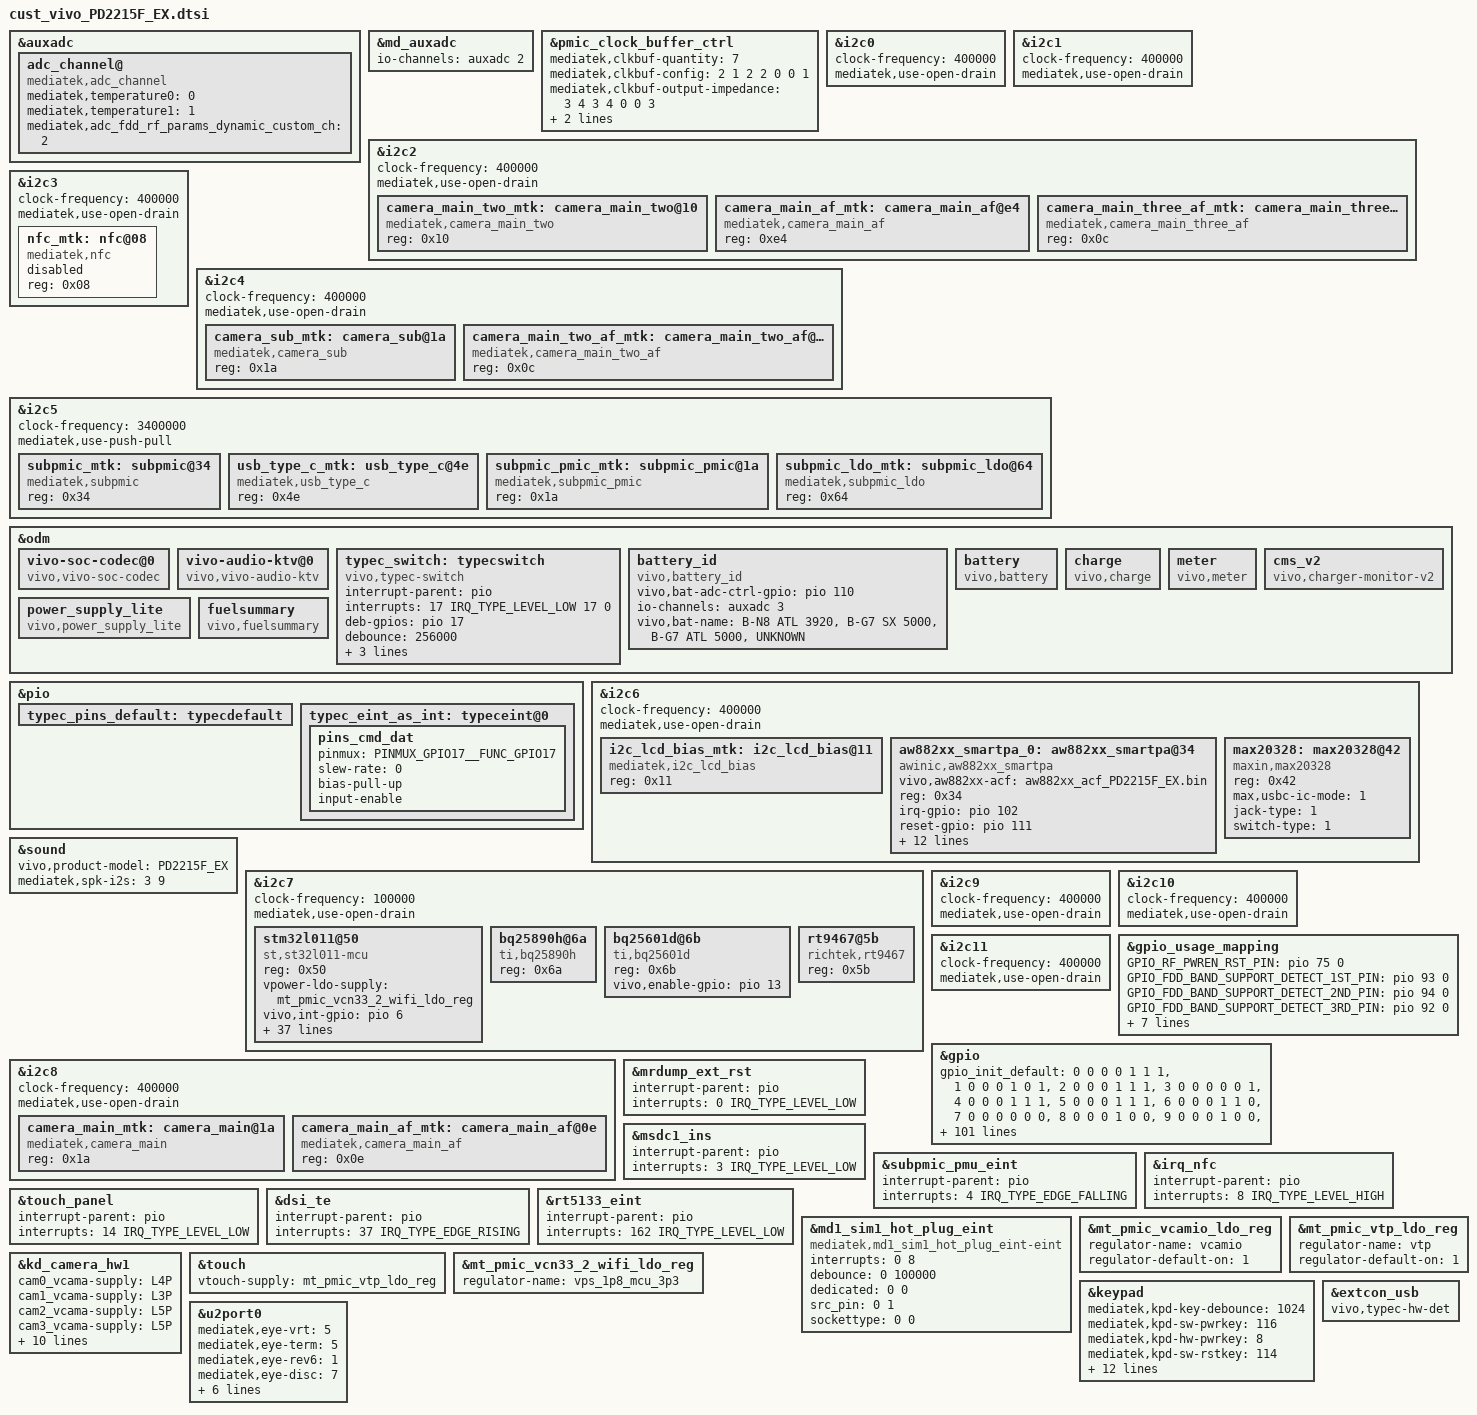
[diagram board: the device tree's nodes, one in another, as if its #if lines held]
/*
* Generated by MTK SP DrvGen Version: 3.5.160809 for MT6877.
* 2022-03-25 15:20:36
* Do Not Modify The File.
* Copyright Mediatek Inc. (c) 2016.
*/

/*************************
* ADC DTSI File
*************************/
#include <dt-bindings/pinctrl/mt6877-pinfunc.h>

&auxadc {
adc_channel@ {
	compatible = "mediatek,adc_channel";
	mediatek,temperature0 = <0>;
	mediatek,temperature1 = <1>;
	mediatek,adc_fdd_rf_params_dynamic_custom_ch = <2>;
	status = "okay";
};
};
&md_auxadc {
io-channels = <&auxadc 2>;
};


/*************************
* CLK_BUF DTSI File
*************************/

&pmic_clock_buffer_ctrl {
mediatek,clkbuf-quantity = <7>;
mediatek,clkbuf-config = <2 1 2 2 0 0 1>;
mediatek,clkbuf-output-impedance = <3 4 3 4 0 0 3>;
mediatek,clkbuf-controls-for-desense = <0 4 0 4 0 0 0>;
status = "okay";
};


/*************************
* I2C DTSI File
*************************/

&i2c0 {
#address-cells = <1>;
#size-cells = <0>;
clock-frequency = <400000>;
mediatek,use-open-drain;
};

&i2c1 {
#address-cells = <1>;
#size-cells = <0>;
clock-frequency = <400000>;
mediatek,use-open-drain;
};

&i2c2 {
#address-cells = <1>;
#size-cells = <0>;
clock-frequency = <400000>;
mediatek,use-open-drain;
camera_main_two_mtk:camera_main_two@10 {
	compatible = "mediatek,camera_main_two";
	reg = <0x10>;
	status = "okay";
};


camera_main_af_mtk:camera_main_af@e4 {
	compatible = "mediatek,camera_main_af";
	reg = <0xe4>;
	status = "okay";
};

camera_main_three_af_mtk:camera_main_three_af@0c {
	compatible = "mediatek,camera_main_three_af";
	reg = <0x0c>;
	status = "okay";
};

};

&i2c3 {
#address-cells = <1>;
#size-cells = <0>;
clock-frequency = <400000>;
mediatek,use-open-drain;
nfc_mtk:nfc@08 {
	compatible = "mediatek,nfc";
	reg = <0x08>;
	status = "disabled";
};

};

&i2c4 {
#address-cells = <1>;
#size-cells = <0>;
clock-frequency = <400000>;
mediatek,use-open-drain;
camera_sub_mtk:camera_sub@1a {
	compatible = "mediatek,camera_sub";
	reg = <0x1a>;
	status = "okay";
};

camera_main_two_af_mtk:camera_main_two_af@0c {
	compatible = "mediatek,camera_main_two_af";
	reg = <0x0c>;
	status = "okay";
};

};

&i2c5 {
#address-cells = <1>;
#size-cells = <0>;
clock-frequency = <3400000>;
mediatek,use-push-pull;
subpmic_mtk:subpmic@34 {
	compatible = "mediatek,subpmic";
	reg = <0x34>;
	status = "okay";
};

usb_type_c_mtk:usb_type_c@4e {
	compatible = "mediatek,usb_type_c";
	reg = <0x4e>;
	status = "okay";
};

subpmic_pmic_mtk:subpmic_pmic@1a {
	compatible = "mediatek,subpmic_pmic";
	reg = <0x1a>;
	status = "okay";
};

subpmic_ldo_mtk:subpmic_ldo@64 {
	compatible = "mediatek,subpmic_ldo";
	reg = <0x64>;
	status = "okay";
};

};

/* vivo audio dxl add start */
&odm {
vivo-soc-codec@0 {
	compatible = "vivo,vivo-soc-codec";
	status = "okay";
};
vivo-audio-ktv@0 {
	compatible = "vivo,vivo-audio-ktv";
	status = "okay";
};

typec_switch:typecswitch {
		compatible = "vivo,typec-switch";
		interrupt-parent = <&pio>;
		interrupts = <17 IRQ_TYPE_LEVEL_LOW 17 0>;
		deb-gpios = <&pio 17 0>;
		debounce = <256000>;
		need_config_Max14743 = <0>;
		pinctrl-names = "default", "typec_eint_as_int";
		pinctrl-0 = <&typec_pins_default>;
		pinctrl-1 = <&typec_eint_as_int>;
		status = "okay";
};
};

&pio {
typec_pins_default: typecdefault {
};
typec_eint_as_int: typeceint@0 {
		pins_cmd_dat {
				pinmux = <PINMUX_GPIO17__FUNC_GPIO17>;
				slew-rate = <0>;
				/*audio_v: archer modfiy bacause cancel hardware comparator,so not the interrupt.*/
				/*bias-disable;*/
				bias-pull-up;
				input-enable;
		};
};
};
/* vivo audio dxl add end */

&i2c6 {
#address-cells = <1>;
#size-cells = <0>;
clock-frequency = <400000>;
mediatek,use-open-drain;
i2c_lcd_bias_mtk:i2c_lcd_bias@11 {
	compatible = "mediatek,i2c_lcd_bias";
	reg = <0x11>;
	status = "okay";
};
/* vivo audio dxl add start */
aw882xx_smartpa_0:aw882xx_smartpa@34 {
	/* AWINIC AW88263 mono SmartPA */
	compatible = "awinic,aw882xx_smartpa";
	vivo,aw882xx-acf = "aw882xx_acf_PD2215F_EX.bin";
	reg = <0x34>;
	irq-gpio = <&pio 102 0>;
	reset-gpio = <&pio 111 0>;
	sound-channel = <0>;
	//monitor-flag = <1>;
	//aw-cali-mode = "aw_debugfs"; //aw_misc or aw_debugfs
	aw-re-min = <6000>;
	aw-re-max = <10000>;
	aw-cali-mode = "aw_attr";
	aw-cali-check = <1>;

	vivo,Type = "speaker";
	vivo,Impedance-Min-mo = <6000>;
	vivo,Impedance-Max-mo = <10000>;
	vivo,Frequency-Min-hz = <500>;
	vivo,Frequency-Max-hz = <1000>;
	vivo,Qt-Min-1000 = <1000>;
	vivo,VendorID = <63>;       /* AW88263 */

	status = "okay";
};
max20328:max20328@42 {
	status = "okay";
	#sound-dai-cells = <0>;
	compatible = "maxin,max20328";
	reg = <0x42>;
	max,usbc-ic-mode = <1>; /* max20328: 0; fsa4480: 1 */
	jack-type = <1>;   /*0:3.5mm, 1:Type-c*/
	switch-type = <1>; /*0:max20328, 1:FS4480*/
};
/* vivo audio dxl add end */
};

&sound {
vivo,product-model = "PD2215F_EX";
mediatek,spk-i2s = <3 9>;
};

&i2c7 {
#address-cells = <1>;
#size-cells = <0>;
clock-frequency = <400000>;
mediatek,use-open-drain;
};

&i2c8 {
#address-cells = <1>;
#size-cells = <0>;
clock-frequency = <400000>;
mediatek,use-open-drain;
camera_main_mtk:camera_main@1a {
	compatible = "mediatek,camera_main";
	reg = <0x1a>;
	status = "okay";
};

camera_main_af_mtk:camera_main_af@0e {
	compatible = "mediatek,camera_main_af";
	reg = <0x0e>;
	status = "okay";
};

};

&i2c9 {
#address-cells = <1>;
#size-cells = <0>;
clock-frequency = <400000>;
mediatek,use-open-drain;
};

&i2c10 {
#address-cells = <1>;
#size-cells = <0>;
clock-frequency = <400000>;
mediatek,use-open-drain;
};

&i2c11 {
#address-cells = <1>;
#size-cells = <0>;
clock-frequency = <400000>;
mediatek,use-open-drain;
};



/*************************
* GPIO DTSI File
*************************/

&gpio_usage_mapping {
GPIO_RF_PWREN_RST_PIN = <&pio 75 0>;
GPIO_FDD_BAND_SUPPORT_DETECT_1ST_PIN = <&pio 93 0>;
GPIO_FDD_BAND_SUPPORT_DETECT_2ND_PIN = <&pio 94 0>;
GPIO_FDD_BAND_SUPPORT_DETECT_3RD_PIN = <&pio 92 0>;
GPIO_SIM2_SIO = <&pio 170 0>;
GPIO_SIM2_SCLK = <&pio 171 0>;
GPIO_SIM2_SRST = <&pio 172 0>;
GPIO_SIM1_SRST = <&pio 173 0>;
GPIO_SIM1_SCLK = <&pio 174 0>;
GPIO_SIM1_SIO = <&pio 175 0>;
GPIO_SIM1_HOT_PLUG = <&pio 176 0>;
};

&gpio{
gpio_init_default = <0 0 0 0 1 1 1>,
	<1 0 0 0 1 0 1>,
	<2 0 0 0 1 1 1>,
	<3 0 0 0 0 0 1>, /* modify by dxl to disable max20328 INT pullen */
	<4 0 0 0 1 1 1>,
	<5 0 0 0 1 1 1>,
	<6 0 0 0 1 1 0>,
	<7 0 0 0 0 0 0>,
	<8 0 0 0 1 0 0>,//pm8008 init
	<9 0 0 0 1 0 0>,
//lcm err_flog
	<10 0 1 0 1 0 1>,
	<11 0 0 0 1 0 0>,
	<12 2 0 0 1 1 0>,
	<13 2 0 0 1 1 0>,
	<14 0 0 0 1 1 1>,
	<15 0 1 0 1 0 1>,
	<16 0 1 0 1 0 1>,
//vddi_en
	<17 0 0 0 1 1 1>,
	<18 0 1 0 1 0 1>,
	<19 7 0 0 1 1 0>,
	<20 0 0 0 0 0 1>,
	<21 0 1 0 1 0 0>,
	<22 0 1 0 1 0 0>,
	<23 0 1 0 1 1 0>,
	<24 1 0 0 0 0 0>,
	<25 1 0 0 0 0 0>,
	<26 1 0 0 1 1 0>,
	<27 1 0 0 0 0 0>,
		<28 1 0 0 1 1 0>,
		<29 0 1 0 0 1 0>,
		<28 0 0 0 0 0 1>,
		<29 0 1 0 1 0 1>,/* FAS4480_ENN opendrain, gpio mode, active low, so pull high */
		<30 1 0 0 1 1 0>,
		<31 0 0 0 0 0 1>,
		<32 0 0 0 0 0 1>, /* vivo audio set FSA4480_INT gpio_mode no pull */
		<33 0 0 0 0 0 0>,
		<34 1 0 0 1 1 0>,
		<35 1 0 0 1 1 0>,
		<36 1 0 0 1 1 1>,
		<37 1 0 0 1 1 1>,
		<38 1 0 0 1 1 1>,
		<39 1 0 0 1 0 1>,
   //lcm te
		<40 0 1 0 0 0 0>,
  //lcm reset
		<41 1 0 0 0 0 1>,
		<42 1 0 0 0 0 1>,
		<43 1 0 0 1 0 1>,
		<44 1 0 0 1 0 1>,
		<45 1 0 0 1 1 1>,
		<46 1 0 0 0 0 0>,
		<47 1 0 0 0 0 0>,
		<48 1 0 0 0 0 0>,
		<49 1 0 0 0 0 0>,
		<50 1 0 0 1 0 0>,
		<51 1 0 0 1 0 0>,
		<52 1 0 0 1 0 0>,
		<53 1 0 0 1 0 0>,
		<54 1 0 0 1 0 1>,
		<55 1 0 0 1 0 0>,
		<56 1 0 0 1 0 0>,
		<57 1 0 0 1 0 0>,
		<58 1 0 0 1 0 0>,
		<59 1 0 0 1 0 0>,
		<60 1 0 0 0 0 1>,
		<61 1 0 0 0 0 1>,
		<62 1 0 0 0 0 1>,
		<63 1 0 0 0 0 1>,
		<64 1 0 0 1 1 1>,
		<65 1 0 0 1 1 1>,
		<66 1 0 0 1 0 1>,
		<67 1 0 0 1 0 1>,
		<68 1 0 0 0 0 0>,
		<69 1 0 0 1 0 0>,
		<70 1 0 0 1 0 1>,
		<71 1 0 0 0 0 1>,
		<72 1 0 0 0 0 1>,
		<73 1 0 0 0 0 1>,
		<74 1 0 0 0 0 1>,
		<75 0 1 1 1 0 1>,
		<76 1 0 0 0 0 1>,
		<77 1 0 0 0 0 1>,
		<78 1 0 0 0 0 1>,
		<79 1 0 0 0 0 1>,
		<80 1 0 0 0 0 1>,
		<81 1 0 0 0 0 1>,
		<82 1 0 0 0 0 0>,
		<83 1 0 0 1 0 0>,
		<84 1 0 0 0 0 0>,
		<85 1 0 0 1 0 0>,
		<86 1 0 0 1 0 1>,
		<87 1 0 0 0 0 1>,
		<88 1 0 0 0 0 1>,
		<89 1 0 0 0 0 1>,
		<90 1 0 0 0 0 1>,
		<91 1 0 0 0 0 1>,
		<92 0 0 0 1 1 1>,
		<93 0 0 0 1 1 1>,
		<94 0 0 0 1 1 1>,
		<95 1 0 0 0 0 1>,
		<96 1 0 0 0 0 1>,
		<97 0 0 0 1 1 1>,
		<98 4 0 0 1 1 0>,
		<99 4 0 0 1 1 0>,
		<100 4 0 0 1 1 0>,
		<101 4 0 0 1 1 0>,
		<102 1 0 0 1 1 0>,
		<103 0 0 0 1 0 0>, //vivo audio set default i2s_mode -> gpio_mode and pull down
		<104 0 0 0 1 0 0>, //vivo audio set default i2s_mode -> gpio_mode and pull down
		<105 1 0 0 1 1 0>,
		<106 0 0 0 1 0 0>, //vivo audio set default i2s_mode -> gpio_mode and pull down
		<107 0 1 1 0 0 1>,
		<108 0 1 0 1 0 1>,
		<109 0 1 0 1 0 0>,
		<110 0 1 0 1 0 0>,
		<111 0 1 0 1 0 0>,
		<112 1 0 0 1 1 0>,
		<113 0 0 0 1 1 0>,
		<114 0 0 0 1 1 0>,
		<115 2 0 0 1 0 1>,
		<116 1 0 0 1 1 1>,
		<117 0 0 0 1 1 0>,
		<118 0 0 0 1 1 0>,
		<119 0 0 0 1 1 0>,
		<120 1 0 0 1 1 0>,
		<121 0 0 0 1 1 0>,
		<122 0 1 0 1 0 1>,
		<123 0 1 0 1 0 1>,
		<124 0 1 0 1 0 1>,
		<125 0 1 0 1 0 1>,
		<126 2 0 0 1 0 0>,
		<127 2 0 0 1 0 0>,
		<128 2 0 0 1 1 1>,
		<129 2 0 0 1 0 1>,
		<130 2 0 0 1 1 1>,
		<131 2 0 0 1 1 1>,
		<132 1 0 0 1 1 1>,
		<133 1 0 0 1 1 1>,
		<134 1 0 0 1 1 1>,
		<135 1 0 0 1 1 1>,
		<136 1 0 0 0 0 1>,//cam2 & cam3 scl8
		<137 1 0 0 0 0 1>,//cam2 & cam3 sda8
		<138 0 1 0 1 0 1>,
    //lcm elvdd_ctrl
		<139 0 1 0 1 0 1>,
   //lcm vddr_en
		<140 0 1 0 1 0 1>,
		<141 0 1 0 1 0 1>,
		<142 0 1 0 1 0 0>,
		<143 1 0 0 0 0 1>,//cam0 scl2
		<144 1 0 0 0 0 1>,//cam0 sda2
		<145 1 0 0 0 0 1>,//cam1 scl4
		<146 1 0 0 0 0 1>,//cam1 sda4
		<147 1 0 0 1 1 1>,//pm8008 scl9
		<148 1 0 0 1 1 1>,//pm8008 sda9
		<149 1 1 0 0 0 0>,//cam0 clk0
		<150 1 1 0 0 0 0>,//cam1 clk1
		<151 1 1 0 0 0 0>,//cam3 clk2
		<152 1 1 0 0 0 0>,//cam2 clk3
		<153 0 0 0 1 1 0>,
		<154 0 0 0 1 1 0>,
		<155 0 0 0 1 1 0>,
		<156 0 0 0 1 1 0>,
		<157 0 0 0 1 1 0>,
		<158 0 0 0 1 1 0>,
		<159 0 0 0 1 1 0>,
		<160 0 0 0 1 1 0>,
		<161 0 0 0 1 1 0>,
		<162 0 0 0 1 1 0>,
		<163 0 0 0 1 1 1>,
		<164 1 0 0 1 1 0>,
		<165 1 0 0 0 0 0>,
		<166 1 0 0 1 1 0>,
		<167 1 0 0 1 1 0>,
		<168 1 0 0 1 1 0>,
		<169 1 0 0 1 1 0>,
		<170 1 0 0 1 1 1>,
		<171 1 0 0 0 0 1>,
		<172 1 0 0 0 0 1>,
		<173 1 0 0 0 0 1>,
		<174 1 0 0 0 0 1>,
		<175 1 0 0 1 1 1>,
		<176 1 0 0 0 0 1>,
		<177 0 0 0 0 0 1>,
		<178 1 0 0 1 0 0>,
		<179 1 0 0 1 0 0>,
		<180 1 0 0 1 1 1>,
		<181 1 0 0 1 1 1>,
		<182 1 0 0 0 1 0>,
		<183 1 0 0 0 0 0>,
		<184 1 0 0 0 1 0>,
		<185 1 0 0 0 0 0>,
		<186 1 0 0 1 1 1>,
		<187 1 0 0 1 1 1>,
		<188 0 1 0 1 1 0>,
		<189 0 1 0 1 1 0>,
		<190 1 0 0 1 1 0>,
		<191 1 0 0 1 1 0>,
		<192 1 0 0 1 1 0>,
		<193 0 0 0 1 1 0>,
		<194 0 0 0 1 1 0>,
		<195 1 0 0 1 1 0>,//wifi 5G SPDT
		<196 0 0 0 1 0 0>,
		<197 0 0 0 1 0 0>,
		<198 0 0 0 1 0 0>,
		<199 0 0 0 1 0 0>,
		<200 0 0 0 1 0 0>,
		<201 0 0 0 1 0 0>,
		<202 0 0 0 1 0 0>,
		<203 0 0 0 1 0 0>,
		<204 0 0 0 1 0 0>,
		<205 0 0 0 1 0 0>,
		<206 0 0 0 1 0 0>,
		<207 0 0 0 1 0 0>,
		<208 0 0 0 1 0 0>;
};


/*************************
 * EINT DTSI File
*************************/

#include <dt-bindings/interrupt-controller/irq.h>
#include <dt-bindings/interrupt-controller/arm-gic.h>

&mrdump_ext_rst {
	interrupt-parent = <&pio>;
	interrupts = <0 IRQ_TYPE_LEVEL_LOW>;
	status = "okay";
};

&msdc1_ins {
	interrupt-parent = <&pio>;
	interrupts = <3 IRQ_TYPE_LEVEL_LOW>;
	status = "okay";
};

&subpmic_pmu_eint {
	interrupt-parent = <&pio>;
	interrupts = <4 IRQ_TYPE_EDGE_FALLING>;
	status = "okay";
};

&irq_nfc {
	interrupt-parent = <&pio>;
	interrupts = <8 IRQ_TYPE_LEVEL_HIGH>;
	status = "okay";
};

&touch_panel {
	interrupt-parent = <&pio>;
	interrupts = <14 IRQ_TYPE_LEVEL_LOW>;
	status = "okay";
};

&dsi_te {
	interrupt-parent = <&pio>;
	interrupts = <37 IRQ_TYPE_EDGE_RISING>;
	status = "okay";
};

&rt5133_eint {
	interrupt-parent = <&pio>;
	interrupts = <162 IRQ_TYPE_LEVEL_LOW>;
	status = "okay";
};



/*************************
 * MD1_EINT DTSI File
*************************/

&md1_sim1_hot_plug_eint {
	compatible = "mediatek,md1_sim1_hot_plug_eint-eint";
	interrupts = <0 8>;
	debounce = <0 100000>;
	dedicated = <0 0>;
	src_pin = <0 1>;
	sockettype = <0 0>;
	status = "okay";
};



/*************************
 * PMIC DTSI File
*************************/

&mt_pmic_vcamio_ldo_reg {
	regulator-name = "vcamio";
	regulator-default-on = <1>; /* 0:skip, 1: off, 2:on */
	status = "okay";
};
&mt_pmic_vtp_ldo_reg {
	regulator-name = "vtp";
	regulator-default-on = <1>; /* 0:skip, 1: off, 2:on */
	status = "okay";
};

&kd_camera_hw1 {
	cam0_vcama-supply = <&L4P>;/*avdd*/
	cam1_vcama-supply = <&L3P>;
	cam2_vcama-supply = <&L5P>;
	cam3_vcama-supply = <&L5P>;

	cam1_vcamd-supply = <&L1P>;/*dvdd*/
	cam2_vcamd-supply = <&L2P>;

	cam0_vcamio-supply = <&mt_pmic_vcamio_ldo_reg>;/*iovdd*/
	cam1_vcamio-supply = <&mt_pmic_vcamio_ldo_reg>;
	cam2_vcamio-supply = <&mt_pmic_vcamio_ldo_reg>;
	cam3_vcamio-supply = <&mt_pmic_vcamio_ldo_reg>;

	cam0_enable_sensor = "s5kgw3sp13pd2215f_mipi_raw";
	cam1_enable_sensor = "s5kjn1sq03pd2215f_mipi_raw";
	cam2_enable_sensor = "hi846pd2215f_mipi_raw";
	cam3_enable_sensor = "gc02m1pd2215f_mipi_raw";
	status = "okay";
};

&touch {
	vtouch-supply = <&mt_pmic_vtp_ldo_reg>;
	status = "okay";
};


/*************************
 * POWER DTSI File
*************************/
/* fuxi add for battery&charge start */
#ifdef CONFIG_VIVO_CHARGING_NEW_ARCH
#ifdef CONFIG_VIVO_CHARGING_DTS_MOVE_HEAD_FILE
&odm {
	battery_id {
		compatible = "vivo,battery_id";
		status = "okay";

		vivo,bat-adc-ctrl-gpio = <&pio 110 0>;

		io-channels = <&auxadc 3>;
		io-channel-names = "battery_id_adc";

		vivo,bat-name = "B-N8 ATL 3920","B-G7 SX 5000","B-G7 ATL 5000","UNKNOWN";
	};

	battery: battery {
		compatible = "vivo,battery";
		status = "okay";
	};

	charge: charge {
		compatible = "vivo,charge";
		status = "okay";
	};

	meter: meter {
		compatible = "vivo,meter";
		status = "okay";
	};

	cms_v2: cms_v2 {
		compatible = "vivo,charger-monitor-v2";
		status = "okay";
	};

	power_supply_lite: power_supply_lite {
		compatible = "vivo,power_supply_lite";
		status = "okay";
	};

	fuelsummary: fuelsummary {
		compatible = "vivo,fuelsummary";
		status = "okay";
	};
};

#else

&pio {
	vivo_scale_8ma: vivo_scale_8ma {
		pins_cmd_dat {
			pinmux = <PINMUX_GPIO60__FUNC_SPMI_M_SCL>,
					 <PINMUX_GPIO61__FUNC_SPMI_M_SDA>;
			drive-strength = <4>;
		};
	};
};

&battery_id {
	status = "okay";
	compatible = "vivo,battery_id";
	pinctrl-names = "vivo_scale_8ma";
	pinctrl-0 = <&vivo_scale_8ma>;
	vivo,bat-adc-ctrl-gpio = <&pio 110 0>;

	io-channels = <&auxadc 3>;
	io-channel-names = "battery_id_adc";

	vivo,bat-name = "B-T3 ATL(NVT) 4.48V 4200","B-R3 AT DS 5000","B-Q7 AT NV 5000";
};

&battery {
	status = "okay";
	compatible = "vivo,battery";

	io-channels = <&auxadc 0>,
		<&auxadc 4>;
	io-channel-names = "primary_board_therm",
		"parallel_board_therm";

	vivo,low-volt-threshold = <3400>;
	vivo,soft-rise-percent = <96>;
	vivo,soft-rise-cumulative = <3>;
	vivo,soft-rise-keep-cumulative = <10>;
	vivo,percnet-sync-delta = <5>;
	vivo,percnet-sync-cumulative = <9>;
	vivo,full-sync-cumulative = <3>;
	vivo,soft-term-percent = <99>;
	vivo,soft-term-cumulative = <36>;
};

&charge {
	status = "okay";
	compatible = "vivo,charge";

	vivo,chg-wdt-s = <40>;
	vivo,re-chg-voltage-mv = <100>;
	vivo,prechg-voltage-mv = <3000>;
	vivo,iprechg-current-ma = <300>;
	vivo,iterm-current-ma = <256>;
	vivo,vreg-voltage-mv = <4460>;
	vivo,vindpm-voltage-mv = <4600>;
	vivo,sys-voltage-min-mv= <3500>;
	vivo,boostv-voltage-mv = <5150>;
	vivo,boostv-ilimit-ma = <1500>;
	vivo,ovp-voltage-mv = <15000>;

	/*
	 * 0  auto detect charging
	 * 1  vivo-normal chargine
	 * 2  vivo-single engine charging
	 * 3  vivo-dual engine charging
	 * 4  vivo-flash charging
	 */
	vivo,charge-scheme = <0>;
	vivo,direct-charger-enable;

	/*
	 * SUPPORTED_ADAPTER_DEFAULT = 0,
	 * SUPPORTED_ADAPTER_VIVO_LV_DCHG_5V_4500MA = 1,
	 * SUPPORTED_ADAPTER_VIVO_HV_DCHG_10V_2250MA = 2,
	 * SUPPORTED_ADAPTER_QC20__9V_2000MA = 3,
	 * SUPPORTED_ADAPTER_VIVO_HV_DCHG_10V_4000MA = 4,
	 * SUPPORTED_ADAPTER_MAX,
	 */
	vivo,supported-adapter = <3>;

	//parameter for 9V2A
	vivo,primary-ichg-max-ma = <2240>;
	vivo,parallel-ichg-max-ma = <1680>;

	vivo,flashchg-spec-ma = <2000 4500 8200>;
	vivo,fastchg-spec-ma = <2000 2100 3800>;
	vivo,normalchg-spec-ma = <2000 1500 2300>;

	/* 0---PMIC; 1---CHGIC */
	vivo,vbus-detect-source = <1>;

	//vivo,usboe-gpio = <&pio 163 0>;

	/*ffc*/
	//vivo,ffc-enable;
	vivo,ffc-iterm-ma = <(-882)>;
	vivo,ffc-vreg-mv = <4510>;
	vivo,ffc-temperature-range = <150 450>;
	vivo,ffc-full-vbat-table-size = <3>;
	vivo,ffc-full-vbat-table = <4510 4510 4470>;
	vivo,ffc-full-ibat-table-size = <3>;
	vivo,ffc-full-ibat-table = <150 199 (-882)>,
		<200 349 (-1279)>,
		<350 449 (-1455)>;

	/*otg reverse chg*/
	vivo,otg-reverse-chg-support;
	vivo,otg-reverse-i-table-size = <5>;
	vivo,otg-reverse-i-table = <471 8888 800 1000>,
		<441 470 1200 1400>,
		<411 440 1600 1800>,
		<0 410 1800 2000>,
		<(-8888) 0 900 1100>;
};

&meter {
	status = "okay";
	compatible = "vivo,meter";

	vivo,load-capacity-delta-max = <60>;
	vivo,poweron-delta-capacity = <20>;
	vivo,poweron-low-capacity = <3>;
	vivo,volt-car-delta = <8>;
	vivo,car-volt-delta = <6>;
	vivo,meter-res-compesate = <6>;
	vivo,ocv-board-compesate = <0>;
	vivo,shipmode-cap-limit = <40>;
	vivo,shipmode-vol-limit = <4000>;

	/* 0---AGING_UNSUPPORTED; 1---DRIVER_SUPPORTED; 2---USPACE_SUPPORTED */
	vivo,battery-aging-support = <2>;

	vivo,capacity-mAh = <4410>;
	/*COLD_CHG COLD_DISCHG NORMAL_CHG NORMAL_DISCHG*/
	vivo,car-tune-value = <1000 1000 1015 1000>,
		<1000 1010 1000 1010>,
		<1000 1000 1000 1000>,
		<1000 1000 1000 1000>,
		<1000 1000 1000 1000>,
		<1000 1000 1000 1000>;

	vivo,bats-qmax = <3360 3460 4150 4195 4245>,
		<4060 4280 4400 4640 4750>,
		<4240 4480 4770 4850 4880>,
		<4611 4630 4747 4805 4786>,
		<4611 4630 4747 4805 4786>,
		<4611 4630 4747 4805 4786>;
	#include "bat_setting/PD2215F_EX__battery_table.dtsi"
	/* car-tune adjust remap */
	vivo,car-tune-adjust-enable;
	vivo,car-tune-adjust-size = <3>;
	vivo,car-tune-adjust-table = <0 10 (355) 7>,
		<11 20 (-30) 9>,
		<21 100 (-30) 12>;
};

&cms_v2 {
	compatible = "vivo,charger-monitor-v2";
	status = "okay";

	default_board: single_charger_board {
		       /*default board: keep in xxxxxx*/
		       support-board-version = "xxxxxx";

		       vivo,bat-det-method = <0>;//r:0, rc:1, eprom:2, ex-fg:3
		       vivo,bat-id-gpio = <&pio 110 0>;

		       /*
			  CHG0__CHARGING_TECHNOLOGY_NONE = 0,
			  CHG1__NORMAL_CHARGING,			//5V/2A normal charging
			  CHG2__QC2_CHARGING,				//9V/2A	QC2.0 charging
			  CHG3__LOW_VOLTAGE_DIRECT_CHARGING,		//5V/4.5A direct charging
			  CHG4__SINGLE_IC_DIV2_CHARGING,		//single IC Div/2 charging
			  CHG5__DUAL_IC_DIV2_CHARGING,			//Dual IC Div/2 charging
			  CHG6__DUAL_IC_DUAL_BATTERY_DIV2_CHARGING,	//Dual IC Div/2 charging
			  CHGX__CHARGING_TECHNOLOGY_MAX,
			*/
		       vivo,charging-technology = <4>;

		       //vivo,no-bat-warning;
		       //vivo,no-chg-timeout;
		       vivo,chg-timeout-mins = <900>;

		       //high temperature charger current control enable
		       vivo,htccc-enable;
		       vivo,htccc-data = <46 55 4100000 100000>;

		       //vivo,fbon-scale-enable;/*disable default*/
		       vivo,fbon-scale-data = <2 100 100>;

		       //vivo,switch-scale-enable;/*disable from rom4.0*/
		       vivo,switch-scale-data = <75 53>;

		       vivo,calling-scale-enable;
		       vivo,calling-scale-data = <100 38>;/*ibat:3900 * 0.54 = 2106,more than 1500,not exit dchg*/
		       vivo,calling-dchg-disable;

		       vivo,weixin-calling-scale-enable;
		       vivo,weixin-calling-scale-data = <100 104>;/*4200mA*/

		       vivo,carlife-scale-enable;
		       vivo,carlife-scale-data = <100 12>;/*500mA*/

		       //vivo,fixed-scale-enable;
		       vivo,fixed-scale-data = <120 3800 0>;/*dchg fixed time adjust the max ibat,disable default*/

		       /*data processing : batt-temp*/
		       vivo,dp-batt-temp-enable;
		       vivo,dp-batt-temp-data = <100>;

		       vivo,vbat-r-comp = <14>;

		       /* charging current for devices in exhibition mode */
		       vivo,exhibition-mode-current-primary = <2048>;
		       vivo,exhibition-mode-current-parallel = <0>;

		       /*default tc parameter*/
		       //single charger ibat scale base on temperature battery cell info:1C/1.2C 3960mah
		       /* tmin, tmax, data, volt1, data_ex1, volt2, data_ex2. */
		       vivo,normal-tc-row-col = <10 9>;
		       vivo,normal-tc-data = <530 8888 0 0 0 0 0 0 0>,
			       <450 529 50 0 0 0 0 0 0>,
			       <200 449 74 0 0 0 0 0 0>,
			       <150 199 74 0 0 0 0 0 0>,
			       <100 149 74 4200000 54 0 0 0 0>,
			       <50 99 54 0 0 0 0 0 0>,
			       <20 49 54 0 0 0 0 0 0>,
			       <(-8888) (19) 0 0 0 0 0 0 0>,
			       <(-8888) (-1) 0 0 0 0 0 0 0>,
			       <(-8888) (-1) 0 0 0 0 0 0 0>;

		       /*flash tc parameter*/
		       vivo,flash-normal-tc-row-col = <11 9>;
		       vivo,flash-normal-tc-data = <530 8888 0 0 0 0 0 0 0>,
			       <450 549 59 0 0 0 0 0 0>,
			       <350 449 181 4200000 136 4300000 118 4460000 89>,
			       <200 349 181 4200000 136 4300000 118 4460000 89>,
			       <150 199 148 4200000 118 4460000 79  0 0>,
			       <100 149 98  0 0 0 0 0 0>,
			       <50 99 70 4200000 49 0 0 0 0>,
			       <20 49 70 4200000 49 0 0 0 0>,
			       <(-50) (19) 0 0 0 0 0 0 0>,
			       <(-100) (-51) 0 0 0 0 0 0 0>,
			       <(-8888) (-101) 0 0 0 0 0 0 0>;

		       /*adjust fastchg base on board temperature and fb off*/
		       vivo,intell-charge-enable;
		       vivo,parallel-temp-enable = <1 1>;//<x y> x:fb-on y:fb-off

		       /* Flash charge fb-on intell param */
		       vivo,primary-fbon-tc-row-col = <7 3>;
		       vivo,primary-fbon-tc-data = <441 8888 1600>,
			       <421 440 3000>,
			       <401 420 3800>,
			       <381 400 4500>,
			       <371 380 5300>,
			       <361 370 6000>,
			       <(-8888) 360 8000>;

		       vivo,parallel-fbon-tc-row-col = <1 3>;
		       vivo,parallel-fbon-tc-data = <(-8888) 8888 0>;

		       /* Flash charge fb-off intell param */
		       vivo,primary-fboff-tc-row-col = <7 3>;
		       vivo,primary-fboff-tc-data = <451 8888 1600>,
		           <431 450 2800>,
		           <411 430 3600>,
			       <391 410 4100>,
			       <361 390 4500>,
			       <341 360 5700>,
			       <(-8888) 340 8000>;
		       vivo,parallel-fboff-tc-row-col = <1 3>;
		       vivo,parallel-fboff-tc-data = <(-8888) 8888 0>;

		       /* 9v Fast charge fb-on intell param */
		       vivo,9v-primary-fbon-tc-row-col = <5 3>;
		       vivo,9v-primary-fbon-tc-data = <441 8888 900>,
			       <421 440 1150>,
			       <410 420 1500>,
			       <381 400 2100>,
			       <(-8888) 380 2500>;
		       vivo,9v-parallel-fbon-tc-row-col = <6 3>;
		       vivo,9v-parallel-fbon-tc-data = <441 8888 300>,
			       <421 440 500>,
			       <381 420 600>,
			       <371 380 1000>,
			       <351 370 1300>,
			       <(-8888) 350 1500>;
		       // second parallel parameter, for rt9467
		       vivo,9v-2nd-parallel-fbon-tc-row-col = <6 3>;
		       vivo,9v-2nd-parallel-fbon-tc-data = <441 8888 300>,
			       <421 440 500>,
			       <381 420 600>,
			       <371 380 1000>,
			       <351 370 1300>,
			       <(-8888) 350 1500>;
		       /* 9v Fast charge fb-off intell param */
		       vivo,9v-primary-fboff-tc-row-col = <5 3>;
		       vivo,9v-primary-fboff-tc-data = <451 8888 900>,
			       <436 450 1350>,
			       <421 435 1700>,
			       <411 420 2300>,
			       <(-8888) 410 2500>;
		       vivo,9v-parallel-fboff-tc-row-col = <7 3>;
		       vivo,9v-parallel-fboff-tc-data = <441 8888 512>,
			       <421 440 700>,
			       <401 420 900>,
			       <381 400 1100>,
			       <371 380 1200>,
			       <361 370 1300>,
			       <(-8888) 360 1500>;
		       // second parallel parameter, for rt9467
		       vivo,9v-2nd-parallel-fboff-tc-row-col = <7 3>;
		       vivo,9v-2nd-parallel-fboff-tc-data = <441 8888 512>,
			       <421 440 700>,
			       <401 420 900>,
			       <381 400 1100>,
			       <371 380 1200>,
			       <361 370 1300>,
			       <(-8888) 360 1500>;

		       /* 5v Normal charge fb-on intell param */
		       vivo,5v-primary-fbon-tc-row-col = <5 3>;
		       vivo,5v-primary-fbon-tc-data = <421 8888 300>,
			       <411 420 500>,
			       <401 410 1000>,
			       <391 400 1500>,
			       <(-8888) 390 2000>;
		       vivo,5v-parallel-fbon-tc-row-col = <1 3>;
		       vivo,5v-parallel-fbon-tc-data = <(-8888) 8888 0>;

		       /* 5v Normal charge fb-off intell param */
		       vivo,5v-primary-fboff-tc-row-col = <5 3>;
		       vivo,5v-primary-fboff-tc-data = <441 8888 300>,
			       <431 440 500>,
			       <421 430 1000>,
			       <411 420 1500>,
			       <(-8888) 410 2000>;
		       vivo,5v-parallel-fboff-tc-row-col = <1 3>;
		       vivo,5v-parallel-fboff-tc-data = <(-8888) 8888 0>;

		       // Direct charging param
		       vivo,direct-charger-enable;//porting_check
		       vivo,ex-bms-psy-name = "bq_bms";

		       // bat_baord, usb_conn, pcb_conn(master_bat_conn), bat_conn
		       vivo,dchg-ntc-protect-enable;
		       vivo,dchg-ntc-protect-data = <750 800 850 850>;

		       vivo,adapter-cooldown-data = <900 850 3400>;
		       /*adapter power derate*/
		       vivo,adapter-power-derate-enable;

		       /* usb connecter protect param
			* USB_PROTECT_NONE = 0,
			* USB_CONN_TEMP_HEAT_PROTECT = BIT(0),
			* USB_ID_PROTECT = BIT(1),
			*/
		       vivo,usb-connecter-protect-enable = <1>;
		       vivo,usb-id-protect-data= <1100 1547 500>;/* 500K, 2M, fcc */
		       vivo,usb-conn-heat-protect-data-row-col = <2 4>;
		       vivo,usb-conn-heat-protect-data= <260 8888 670 620>,
			       <(-8888) 259 570 520>;

		       /*
			* max vbus of adapter:11v, max ibus of adapter:5A
			* min voltage of battery for half chg:3500mV,max voltage of battery for half charge:4100mV,
			* 5V2A charge min current threshold: 1000mA,5V2A charge max current threshold:2100mA,
			* flash charge min current threshold:5000mA,flash charge max current threshold:11000mA
			*/

		       /*default parameter*/
		       vivo,charge-param-judge-threshold = <9 2 3500 4300 1000 2300 2100 3800>;
		       /* factory mode charging test param */
		       vivo,charge-test-param-row-col = <12 3>;
		       vivo,charge-test-param-data = <0 0 5500>, /* cable resistance, min value, max value */
			       <0 0 5500>, /* master ibus, min ibus, max ibus */
			       <0 0 5500>, /* slave ibus, min ibus, max ibus */
			       <1 20 40>, /* batt therm ntc, min value, max value */
			       <1 20 45>, /* board therm ntc, min value, max value */
			       <1 20 50>, /* sub charger ntc, min value, max value */
			       <0 20 45>, /* usb con ntc, min value, max value */
			       <0 20 45>, /* usb con 1 ntc, double usb NTC, min value, max value */
			       <0 20 45>, /* bat btb master ntc, min value, max value */
			       <0 20 50>, /* bat btb sub ntc, min value, max value */
			       <0 20 50>, /* bat board ntc, min value, max value */
			       <0 20 50>; /* wireless charge coil ntc, min value, max value */

		       /*flash parameter*/
		       vivo,flash-charge-param-judge-threshold = <11 4 3500 4100 1000 2300 4500 8200>;
		       /* factory mode charging test param */
		       vivo,flash-charge-test-param-row-col = <12 3>;
		       vivo,flash-charge-test-param-data = <1 0 5500>, /* cable resistance, min value, max value */
			       <1 0 5500>, /* master ibus, min ibus, max ibus */
			       <0 0 5500>, /* slave ibus, min ibus, max ibus */
			       <1 20 40>, /* batt therm ntc, min value, max value */
			       <1 20 45>, /* board therm ntc, min value, max value */
			       <0 20 50>, /* sub charger ntc, min value, max value */
			       <1 20 45>, /* usb con ntc, min value, max value */
			       <0 20 45>, /* usb con 1 ntc, double usb NTC, min value, max value */
			       <1 20 45>, /* bat btb master ntc, min value, max value */
			       <0 20 50>, /* bat btb sub ntc, min value, max value */
			       <1 20 50>, /* bat board ntc, min value, max value */
			       <0 20 50>; /* wireless charge coil ntc, min value, max value */
			#include "bat_setting/PD2215F_EX_battery_chg_params.dtsi"
	       };
};

&power_supply_lite {
	status = "okay";
	compatible = "vivo,power_supply_lite";
};

&fuelsummary {
	status = "okay";
	compatible = "vivo,fuelsummary";

	/************************************************************
	 *
	 *  0   vivo-fastchg
	 *  1   qcom-dualchg
	 *  2   mtk-dualchg
	 *  3   qcom-normchg
	 *  4   mtk-normchg
	 *
	 ***********************************************************/
	chg-scheme = <2>;
	fex-version = <3>;
	fbon-ibat = <(-900)>;
	fboff-ibat = <(-1000)>;

	/* 0---AGING_UNSUPPORTED; 1---DRIVER_SUPPORTED; 2---USPACE_SUPPORTED */
	vivo,battery-aging-support = <2>;
};

#endif

&mt_pmic_vcn33_2_wifi_ldo_reg {
	regulator-name = "vps_1p8_mcu_3p3";
};

&i2c7 {
	#address-cells = <1>;
	#size-cells = <0>;
	status = "okay";
	clock-frequency = <100000>;

	stm32l011@50 {
		compatible = "st,st32l011-mcu";
		reg = <0x50>;

		vpower-ldo-supply = <&mt_pmic_vcn33_2_wifi_ldo_reg>;
		//vivo,power-gpio = <&pio 141 0>;//ZC_LDO_EN
		vivo,int-gpio = <&pio 6 0>;//MCU_INT_AP
		vivo,usbsel-gpio = <&pio 109 0>;//USB_SW_EN
		vivo,shift-en-gpio = <&pio 10 0>;//SHIFT_EN
		//vivo,usben-gpio = <&pio 27 0>;
		vivo,sbu-pwr-gpio = <&pio 19 0>;
		//vivo,chgic-version-gpio = <&pio 87 0>;
		vivo,chgic-version-reverse;

		ti,temp-cold-degc = <2>;
		ti,temp-hot-degc = <43>;
		vivo,total-limit-max-ma = <8000>;
		vivo,bigdata-collect-time-limit = <95>;//seconds
		vivo,direct-charger-enable;//porting_check

		/*FFC charge: */
		vivo,ffc-support;
		vivo,ffc-temperature-range = <150 450>;
		//vivo,ffc-param-tuning-enable = <1963>;
		vivo,ffc-cc-to-cv-ibat-thr-rc = <1 3>;
		/*<Tmin Tmax current>*/
		vivo,ffc-cc-to-cv-ibat-thr-table = <150 450 3800>;
		vivo,ffc-dchg-cv-mv-rc = <3 2>;
		/*btb_cv,fg_cv*/
		vivo,ffc-dchg-cv-mv-table = <4430 4430>,/*default*/
			<4531 4531>,/*single_charging*/
			<4528 4528>;/*dual_charging*/

		vivo,cout-int-gpio = <&pio 7 0>;

		vivo,sbu-cable-id-detect-enable;
		vivo,sbu-detect-rely-usb-switch;

		vivo,bat-board-temp-enable = <3>;
		vivo,usb-conn-temp-enable = <3>;
		vivo,bat-conn-temp-enable = <1>;

		vivo,master-bat-conn-temp-enable = <0>;
		vivo,dchg-exit-ntc-threshold = <700 650 700 700 1200>;

		/* BQ25970_SINGLE_DCHG:
		 * DCHG_SINGLE_TYPE_22P5W = 0,
		 * DCHG_SINGLE_TYPE_33W = 1,
		 * DCHG_SINGLE_TYPE_44W = 2,
		 * BQ25970_DUAL_DCHG:DCHG_DUAL_TYPE_44W = 3,
		 */
		vivo,dchg-supported-type = <1>;
		/*adapter power derate*/
		vivo,adapter-power-derate-enable;

		//vivo,single-charger-enable;
		vivo,adapter-sha-encryption;

		io-channels = <&auxadc 5>,
			<&auxadc 6>,
			<&auxadc 4>;

		io-channel-names = "sbu2_cable_id_adc",
			"sbu1_cable_id_adc",
			"usb_conn_temp";

		/*cable r limit table :
		  <rmin,rmax, dchg_ibus_max, cable_id_type, limit_count>
		  cable_id_type: 0:effective cable id, 1:other(default) cable id
		 */
		vivo,cable-r-limit-table-rc = <9 5>;
		vivo,cable-r-limit-table = <(-8888) 278 4000 0 0>,
			<279 336 3000 0 0>,
			<337 400 2250 0 0>,
			<401 511 1800 0 0>,
			<512 8888 0 0 0>,
			<(-8888) 314 3000 1 0>,
			<315 400 2250 1 0>,
			<401 511 1800 1 0>,
			<512 8888 0 1 0>;

		/*load firmware profile*/
		vivo,fw-id-range-pct = <100>;
		#include "bat_setting/mcu-firmware-data-44w-nation-ln8000-notbat-notbus.dtsi"
	};

	bq25890h@6a {
		compatible = "ti,bq25890h";
		reg = <0x6a>;

		//vivo,int-gpio = <&pio 11 0>;
	};

	bq25601d@6b {
		compatible = "ti,bq25601d";
		reg = <0x6b>;

		//vivo,int-gpio = <&pio 11 0>;
		vivo,enable-gpio = <&pio 13 0>;
	};

	rt9467@5b {
		compatible = "richtek,rt9467";
		reg = <0x5b>;

		//vivo,int-gpio = <&pio 3 0>;
		//vivo,enable-gpio = <&pio 166 0>;
	};
};
#endif
/* fuxi add for battery&charge end */
/*************************
 * KPD DTSI File
*************************/

&keypad {
	mediatek,kpd-key-debounce = <1024>;
	mediatek,kpd-sw-pwrkey = <116>;
	mediatek,kpd-hw-pwrkey = <8>;
	mediatek,kpd-sw-rstkey  = <114>;
	mediatek,kpd-hw-rstkey = <17>;
	mediatek,kpd-use-extend-type = <0>;
	/*HW Keycode [0~71] -> Linux Keycode*/
	mediatek,kpd-hw-map-num = <72>;
	mediatek,kpd-hw-init-map = <115 0 0 0 0 0 0 0 0 0 0 0 0 0 0 0 0 0 0 0 0 0 0 0 0 0 0 0 0 0 0 0 0 0 0 0 0 0 0 0 0 0 0 0 0 0 0 0 0 0 0 0 0 0 0 0 0 0 0 0 0 0 0 0 0 0 0 0 0 0 0 0 >;
	mediatek,kpd-pwrkey-eint-gpio = <0>;
	mediatek,kpd-pwkey-gpio-din  = <0>;
	mediatek,kpd-hw-dl-key0 = <17>;
	mediatek,kpd-hw-dl-key1 = <0>;
	mediatek,kpd-hw-dl-key2 = <8>;
	mediatek,kpd-hw-recovery-key = <17>;
	mediatek,kpd-hw-factory-key = <0>;
	status = "okay";
};

//vivo panyaqin add for usb eye begin
&u2port0{
    mediatek,eye-vrt = <5>; /* 0~7 */
    mediatek,eye-term = <5>; /* 0~7 */
    mediatek,eye-rev6 = <1>; /* 0~3 */
    mediatek,eye-disc = <7>; /* 0~8 */
    mediatek,eye-intr = <0x1e>; /* 0~0xlf */
    mediatek,host-eye-vrt = <6>; /* 0~7 */
    mediatek,host-eye-term = <6>; /* 0~7 */
    mediatek,host-eye-rev6 = <1>; /* 0~3 */
    mediatek,host-eye-disc = <0xf>; /* 0~8 */
    mediatek,host-eye-intr = <0x12>; /* 0~0xlf */
};

&extcon_usb{
    vivo,typec-hw-det;
};
//vivo panyaqin add for usb eye begin

